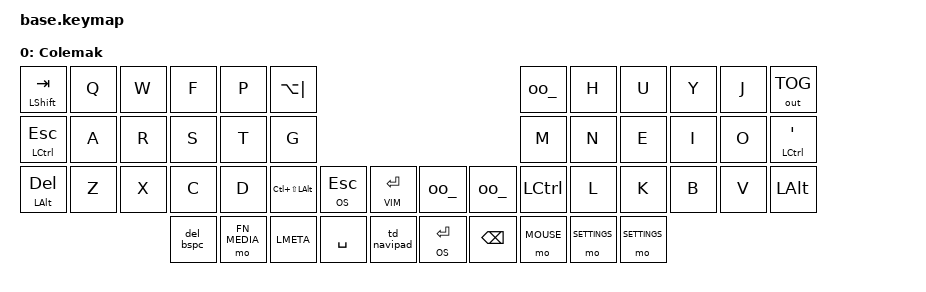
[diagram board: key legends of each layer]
/ {
    keymap {
        compatible = "zmk,keymap";
        colemak {
            label = "Colemak";
            sensor-bindings = <&enc_up_down>;
            bindings = <
//                ╭─────────┬─────┬─────┬───────────┬────────────┬─────────────────╮                                              ╭─────────┬────────────┬────────────┬─────┬─────┬───────────────╮
//                │  ⇧ │ ⭾  │  Q  │  W  │     F     │     P      │                │                                              │   ---   │     H      │     U      │  Y  │  J  │ Toggle Output │
//                ├─────────┼─────┼─────┼───────────┼────────────┼─────────────────┤                                              ├─────────┼────────────┼────────────┼─────┼─────┼───────────────┤
//                │  ⌃ │ ⎋  │  A  │  R  │     S     │     T      │        G        │                                              │    M    │     N      │     E      │  I  │  O  │     ⌃ │ '     │
//                ├─────────┼─────┼─────┼───────────┼────────────┼─────────────────┼───────────┬────────────╮   ╭───────────┬─────┼─────────┼────────────┼────────────┼─────┼─────┼───────────────┤
//                │  ⎇ │ ⌦  │  Z  │  X  │     C     │     D      │ lctl(lsft( ⎇ )) │ lt OS  ⎋  │ lt VIM  ⏎  │   │    ---    │ --- │    ⌃    │     L      │     K      │  B  │  V  │       ⎇       │
//                ╰─────────┴─────┴─────┼───────────┼────────────┼─────────────────┼───────────┼────────────┤   ├───────────┼─────┼─────────┼────────────┼────────────┼─────┴─────┴───────────────╯
//                                      │ &del_bspc │  FN_MEDIA │        ◆        │     ␣     │  navipad   │   │ lt OS  ⏎  │  ⌫  │  MOUSE │  SETTINGS │  SETTINGS │
//                                      ╰───────────┴────────────┴─────────────────┴───────────┴────────────╯   ╰───────────┴─────┴─────────┴────────────┴────────────╯
              &mt LSHIFT TAB   &kp Q   &kp W   &kp F       &kp P          &kp LA(PIPE)                                                              _oo_        &kp H          &kp U          &kp Y   &kp J   &out OUT_TOG
              &mt LCTRL ESC    &kp A   &kp R   &kp S       &kp T          &kp G                                                                     &kp M       &kp N          &kp E          &kp I   &kp O   &mt LCTRL SQT
              &mt LALT DEL     &kp Z   &kp X   &kp C       &kp D          &kp LC(LS(LALT))   &lt OS ESC   &lt VIM RET       _oo_         _oo_       &kp LCTRL   &kp L          &kp K          &kp B   &kp V   &kp LALT
                                               &del_bspc   &mo FN_MEDIA   &kp LMETA          &kp SPACE    &td_navipad       &lt OS RET   &kp BSPC   &mo MOUSE   &mo SETTINGS   &mo SETTINGS
            >;
        };
	};
    behaviors {
        enc_kp: enc_kp {
            compatible = "zmk,behavior-sensor-rotate-var";
            label = "ENC_KP";
            #sensor-binding-cells = <2>;
            bindings = <&kp>, <&kp>;
        };
        enc_up_down: enc_up_down {
            compatible = "zmk,behavior-sensor-rotate";
            label = "ENC_UP_DOWN";
            #sensor-binding-cells = <0>;
            // mod morphs
            bindings = <&ctrl_down>, <&ctrl_up>;
        };
		TAP_DANCE(td_navipad, &mo_NAVIPAD, &tog NAVIPAD);
    };
	macros {
		MACRO_BEFORE_AFTER(mo_NAVIPAD, &mo NAVIPAD, , &mo NUMPAD)
	};
	conditional_layers {
		compatible = "zmk,conditional-layers";
		tri_layer {
			if-layers = <VIM OS>;
			then-layer = <FN_KEYS>;
		};
	};
};
